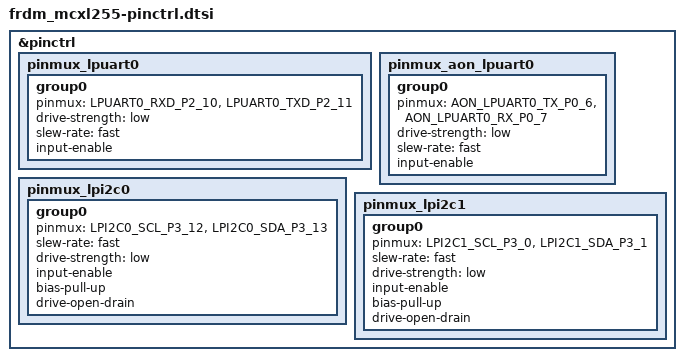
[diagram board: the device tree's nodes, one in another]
/*
 * Copyright 2025 NXP
 * SPDX-License-Identifier: Apache-2.0
 */

#include <nxp/mcx/MCXL255VDF-pinctrl.h>

&pinctrl {
	pinmux_lpuart0: pinmux_lpuart0 {
		group0 {
			pinmux = <LPUART0_RXD_P2_10>,
				 <LPUART0_TXD_P2_11>;
			drive-strength = "low";
			slew-rate = "fast";
			input-enable;
		};
	};

	pinmux_aon_lpuart0: pinmux_aon_lpuart0 {
		group0 {
			pinmux = <AON_LPUART0_TX_P0_6>,
				 <AON_LPUART0_RX_P0_7>;
			drive-strength = "low";
			slew-rate = "fast";
			input-enable;
		};
	};

	pinmux_lpi2c0: pinmux_lpi2c0 {
		group0 {
			pinmux = <LPI2C0_SCL_P3_12>,
				 <LPI2C0_SDA_P3_13>;
			slew-rate = "fast";
			drive-strength = "low";
			input-enable;
			bias-pull-up;
			drive-open-drain;
		};
	};

	pinmux_lpi2c1: pinmux_lpi2c1 {
		group0 {
			pinmux = <LPI2C1_SCL_P3_0>,
				 <LPI2C1_SDA_P3_1>;
			slew-rate = "fast";
			drive-strength = "low";
			input-enable;
			bias-pull-up;
			drive-open-drain;
		};
	};
};
